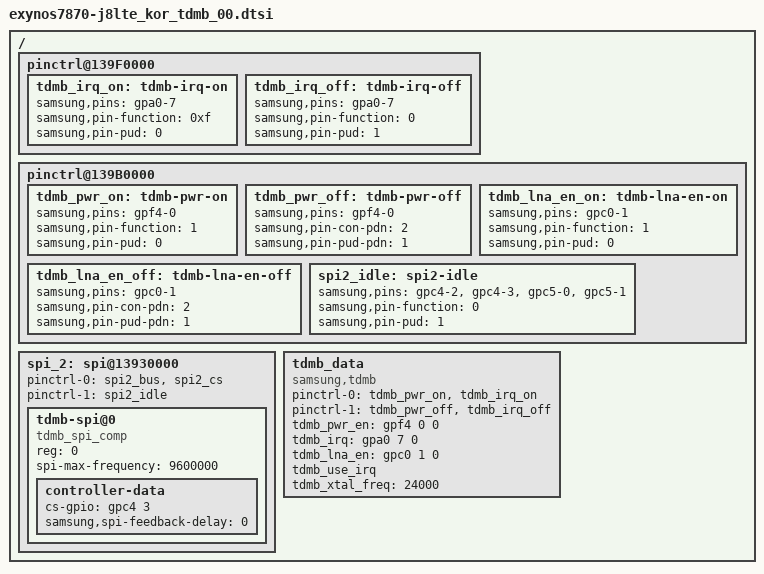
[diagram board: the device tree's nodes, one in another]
/*
 * SAMSUNG UNIVERSAL7870 board device tree source
 *
 * Copyright (c) 2013 Samsung Electronics Co., Ltd.
 *		http://www.samsung.com
 *
 * This program is free software; you can redistribute it and/or modify
 * it under the terms of the GNU General Public License version 2 as
 * published by the Free Software Foundation.
*/

/{
	pinctrl@139F0000 {
		tdmb_irq_on: tdmb-irq-on {
			samsung,pins = "gpa0-7";
			samsung,pin-function = <0xf>; /* EXT_INT */
			samsung,pin-pud = <0>;	/* PULL NONE */
		};
		tdmb_irq_off: tdmb-irq-off {
			samsung,pins = "gpa0-7";
			samsung,pin-function = <0>; /* INPUT */
			samsung,pin-pud = <1>;	/* PULL DOWN */
		};
	};
	pinctrl@139B0000 {
		tdmb_pwr_on: tdmb-pwr-on {
			samsung,pins = "gpf4-0";
			samsung,pin-function = <1>; /* OUTPUT */
			samsung,pin-pud = <0>;	/* PULL NONE */
		};
		tdmb_pwr_off: tdmb-pwr-off {
			samsung,pins = "gpf4-0";
			samsung,pin-con-pdn = <2>; /* INPUT */
			samsung,pin-pud-pdn = <1>;	/* PULL DOWN */
		};

		tdmb_lna_en_on: tdmb-lna-en-on {
			samsung,pins = "gpc0-1";
			samsung,pin-function = <1>; /* OUTPUT */
			samsung,pin-pud = <0>;	/* PULL NONE */
		};
		tdmb_lna_en_off: tdmb-lna-en-off {
			samsung,pins = "gpc0-1";
			samsung,pin-con-pdn = <2>; /* INPUT */
			samsung,pin-pud-pdn = <1>;	/* PULL DOWN */
		};

		spi2_idle: spi2-idle {
			samsung,pins = "gpc4-2", "gpc4-3", "gpc5-0", "gpc5-1";
			samsung,pin-function = <0>; /* INPUT */
			samsung,pin-pud = <1>;  /* PULL DOWN */
		};
	};

	spi_2: spi@13930000 {
		status = "ok";
		pinctrl-names = "default", "idle";
		pinctrl-0 = <&spi2_bus &spi2_cs>;
		pinctrl-1 = <&spi2_idle>;

		tdmb-spi@0 {
			compatible = "tdmb_spi_comp";
			reg = <0>;
			spi-max-frequency = <9600000>;
			controller-data {
				cs-gpio = <&gpc4 3 0>;
				samsung,spi-feedback-delay = <0>;
			};
		};
	};

	tdmb_data {
		compatible = "samsung,tdmb";
		pinctrl-names = "tdmb_on", "tdmb_off";
		pinctrl-0 = <&tdmb_pwr_on &tdmb_irq_on>;
		pinctrl-1 = <&tdmb_pwr_off &tdmb_irq_off>;
		tdmb_pwr_en = <&gpf4 0 0>;
		tdmb_irq = <&gpa0 7 0>;
		tdmb_lna_en = <&gpc0 1 0>;
		tdmb_use_irq;
		tdmb_xtal_freq = <24000>;
	};

};
